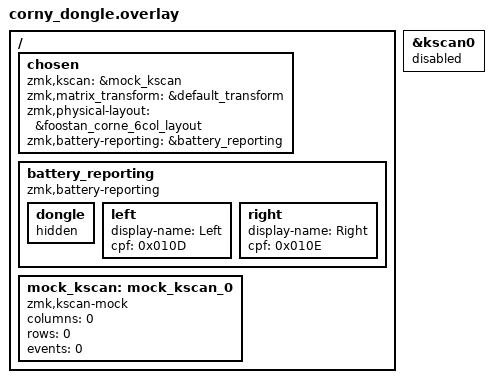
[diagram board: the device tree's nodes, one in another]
#include "corny.dtsi"

/ {
    chosen {
        zmk,kscan = &mock_kscan;
        zmk,matrix_transform = &default_transform;
        zmk,physical-layout = &foostan_corne_6col_layout;
        zmk,battery-reporting = &battery_reporting;
    };

    battery_reporting: battery_reporting {
        compatible = "zmk,battery-reporting";

        /* Hide the dongle itself — it has no battery */
        dongle {
            hidden;
        };

        left {
            display-name = "Left";
            cpf = <0x010D>;
        };

        right {
            display-name = "Right";
            cpf = <0x010E>;
        };
    };

    mock_kscan: mock_kscan_0 {
        compatible = "zmk,kscan-mock";
        columns = <0>;
        rows = <0>;
        events = <0>;
    };
};

/* Disable the real kscan — dongle has no matrix */
&kscan0 {
    status = "disabled";
};
